# cc13x2_cc26x2 register map
File version: 2.1
CPU: CM4 r0p1, little endian, MPU, FPU, 3 interrupt priority bits
Registers are 32-bit, read-write, reset 0x0 unless marked. A register's access mark holds for its fields unless they carry their own. Offsets are from the block's base; [hi:lo] are bit positions; {n}, {i} and the like mark numbered series.

## EVENT — Event Fabric Component Definition
Base 0x40083000
0x00 CPUIRQSEL0 ro reset 0x4 — Output Selection for CPU Interrupt 0
  [6:0] EV
0x04 CPUIRQSEL1 ro reset 0x9 — Output Selection for CPU Interrupt 1
  [6:0] EV
0x08 CPUIRQSEL2 ro reset 0x1E — Output Selection for CPU Interrupt 2
  [6:0] EV
0x0C CPUIRQSEL3 ro reset 0x1F — Output Selection for CPU Interrupt 3
  [6:0] EV
0x10 CPUIRQSEL4 ro reset 0x7 — Output Selection for CPU Interrupt 4
  [6:0] EV
0x14 CPUIRQSEL5 ro reset 0x24 — Output Selection for CPU Interrupt 5
  [6:0] EV
0x18 CPUIRQSEL6 ro reset 0x1C — Output Selection for CPU Interrupt 6
  [6:0] EV
0x1C CPUIRQSEL7 ro reset 0x22 — Output Selection for CPU Interrupt 7
  [6:0] EV
0x20 CPUIRQSEL8 ro reset 0x23 — Output Selection for CPU Interrupt 8
  [6:0] EV
0x24 CPUIRQSEL9 ro reset 0x1B — Output Selection for CPU Interrupt 9
  [6:0] EV
0x28 CPUIRQSEL10 ro reset 0x1A — Output Selection for CPU Interrupt 10
  [6:0] EV
0x2C CPUIRQSEL11 ro reset 0x19 — Output Selection for CPU Interrupt 11
  [6:0] EV
0x30 CPUIRQSEL12 ro reset 0x8 — Output Selection for CPU Interrupt 12
  [6:0] EV
0x34 CPUIRQSEL13 ro reset 0x1D — Output Selection for CPU Interrupt 13
  [6:0] EV
0x38 CPUIRQSEL14 ro reset 0x18 — Output Selection for CPU Interrupt 14
  [6:0] EV
0x3C CPUIRQSEL15 ro reset 0x10 — Output Selection for CPU Interrupt 15
  [6:0] EV
0x40 CPUIRQSEL16 ro reset 0x11 — Output Selection for CPU Interrupt 16
  [6:0] EV
0x44 CPUIRQSEL17 ro reset 0x12 — Output Selection for CPU Interrupt 17
  [6:0] EV
0x48 CPUIRQSEL18 ro reset 0x13 — Output Selection for CPU Interrupt 18
  [6:0] EV
0x4C CPUIRQSEL19 ro reset 0xC — Output Selection for CPU Interrupt 19
  [6:0] EV
0x50 CPUIRQSEL20 ro reset 0xD — Output Selection for CPU Interrupt 20
  [6:0] EV
0x54 CPUIRQSEL21 ro reset 0xE — Output Selection for CPU Interrupt 21
  [6:0] EV
0x58 CPUIRQSEL22 ro reset 0xF — Output Selection for CPU Interrupt 22
  [6:0] EV
0x5C CPUIRQSEL23 ro reset 0x5D — Output Selection for CPU Interrupt 23
  [6:0] EV
0x60 CPUIRQSEL24 ro reset 0x27 — Output Selection for CPU Interrupt 24
  [6:0] EV
0x64 CPUIRQSEL25 ro reset 0x26 — Output Selection for CPU Interrupt 25
  [6:0] EV
0x68 CPUIRQSEL26 ro reset 0x15 — Output Selection for CPU Interrupt 26
  [6:0] EV
0x6C CPUIRQSEL27 ro reset 0x64 — Output Selection for CPU Interrupt 27
  [6:0] EV
0x70 CPUIRQSEL28 ro reset 0xB — Output Selection for CPU Interrupt 28
  [6:0] EV
0x74 CPUIRQSEL29 ro reset 0x1 — Output Selection for CPU Interrupt 29
  [6:0] EV
0x78 CPUIRQSEL30 — Output Selection for CPU Interrupt 30
  [6:0] EV
0x7C CPUIRQSEL31 ro reset 0x6A — Output Selection for CPU Interrupt 31
  [6:0] EV
0x80 CPUIRQSEL32 ro reset 0x73 — Output Selection for CPU Interrupt 32
  [6:0] EV
0x84 CPUIRQSEL33 ro reset 0x68 — Output Selection for CPU Interrupt 33
  [6:0] EV
0x88 CPUIRQSEL34 ro reset 0x6 — Output Selection for CPU Interrupt 34
  [6:0] EV
0x8C CPUIRQSEL35 ro reset 0x38 — Output Selection for CPU Interrupt 35
  [6:0] EV
0x90 CPUIRQSEL36 ro reset 0x25 — Output Selection for CPU Interrupt 36
  [6:0] EV
0x94 CPUIRQSEL37 ro reset 0x5 — Output Selection for CPU Interrupt 37
  [6:0] EV
0x100 RFCSEL0 ro reset 0x3D — Output Selection for RFC Event 0
  [6:0] EV
0x104 RFCSEL1 ro reset 0x3E — Output Selection for RFC Event 1
  [6:0] EV
0x108 RFCSEL2 ro reset 0x3F — Output Selection for RFC Event 2
  [6:0] EV
0x10C RFCSEL3 ro reset 0x40 — Output Selection for RFC Event 3
  [6:0] EV
0x110 RFCSEL4 ro reset 0x41 — Output Selection for RFC Event 4
  [6:0] EV
0x114 RFCSEL5 ro reset 0x42 — Output Selection for RFC Event 5
  [6:0] EV
0x118 RFCSEL6 ro reset 0x43 — Output Selection for RFC Event 6
  [6:0] EV
0x11C RFCSEL7 ro reset 0x44 — Output Selection for RFC Event 7
  [6:0] EV
0x120 RFCSEL8 ro reset 0x77 — Output Selection for RFC Event 8
  [6:0] EV
0x124 RFCSEL9 reset 0x2 — Output Selection for RFC Event 9
  [6:0] EV
0x200 GPT0ACAPTSEL reset 0x55 — Output Selection for GPT0 0
  [6:0] EV
0x204 GPT0BCAPTSEL reset 0x56 — Output Selection for GPT0 1
  [6:0] EV
0x300 GPT1ACAPTSEL reset 0x57 — Output Selection for GPT1 0
  [6:0] EV
0x304 GPT1BCAPTSEL reset 0x58 — Output Selection for GPT1 1
  [6:0] EV
0x400 GPT2ACAPTSEL reset 0x59 — Output Selection for GPT2 0
  [6:0] EV
0x404 GPT2BCAPTSEL reset 0x5A — Output Selection for GPT2 1
  [6:0] EV
0x508 UDMACH1SSEL ro reset 0x31 — Output Selection for DMA Channel 1 SREQ
  [6:0] EV
0x50C UDMACH1BSEL ro reset 0x30 — Output Selection for DMA Channel 1 REQ
  [6:0] EV
0x510 UDMACH2SSEL ro reset 0x33 — Output Selection for DMA Channel 2 SREQ
  [6:0] EV
0x514 UDMACH2BSEL ro reset 0x32 — Output Selection for DMA Channel 2 REQ
  [6:0] EV
0x518 UDMACH3SSEL ro reset 0x29 — Output Selection for DMA Channel 3 SREQ
  [6:0] EV
0x51C UDMACH3BSEL ro reset 0x28 — Output Selection for DMA Channel 3 REQ
  [6:0] EV
0x520 UDMACH4SSEL ro reset 0x2B — Output Selection for DMA Channel 4 SREQ
  [6:0] EV
0x524 UDMACH4BSEL ro reset 0x2A — Output Selection for DMA Channel 4 REQ
  [6:0] EV
0x528 UDMACH5SSEL ro reset 0x35 — Output Selection for DMA Channel 5 SREQ
  [6:0] EV
0x52C UDMACH5BSEL ro reset 0x34 — Output Selection for DMA Channel 5 REQ
  [6:0] EV
0x530 UDMACH6SSEL ro reset 0x37 — Output Selection for DMA Channel 6 SREQ
  [6:0] EV
0x534 UDMACH6BSEL ro reset 0x36 — Output Selection for DMA Channel 6 REQ
  [6:0] EV
0x538 UDMACH7SSEL ro reset 0x75 — Output Selection for DMA Channel 7 SREQ
  [6:0] EV
0x53C UDMACH7BSEL ro reset 0x76 — Output Selection for DMA Channel 7 REQ
  [6:0] EV
0x540 UDMACH8SSEL ro reset 0x74 — Output Selection for DMA Channel 8 SREQ ingle request is ignored for this channel
  [6:0] EV
0x544 UDMACH8BSEL ro reset 0x74 — Output Selection for DMA Channel 8 REQ
  [6:0] EV
0x548 UDMACH9SSEL reset 0x45 — Output Selection for DMA Channel 9 SREQ MA_DONE for the corresponding DMA channel is available as interrupt on GPT0 as GPT0:RIS.DMAARIS
  [6:0] EV
0x54C UDMACH9BSEL reset 0x4D — Output Selection for DMA Channel 9 REQ MA_DONE for the corresponding DMA channel is available as interrupt on GPT0 as GPT0:RIS.DMAARIS
  [6:0] EV
0x550 UDMACH10SSEL reset 0x46 — Output Selection for DMA Channel 10 SREQ MA_DONE for the corresponding DMA channel is available as interrupt on GPT0 as GPT0:RIS.DMABRIS
  [6:0] EV
0x554 UDMACH10BSEL reset 0x4E — Output Selection for DMA Channel 10 REQ MA_DONE for the corresponding DMA channel is available as interrupt on GPT0 as GPT0:RIS.DMABRIS
  [6:0] EV
0x558 UDMACH11SSEL reset 0x47 — Output Selection for DMA Channel 11 SREQ MA_DONE for the corresponding DMA channel is available as interrupt on GPT1 as GPT1:RIS.DMAARIS
  [6:0] EV
0x55C UDMACH11BSEL reset 0x4F — Output Selection for DMA Channel 11 REQ MA_DONE for the corresponding DMA channel is available as interrupt on GPT1 as GPT1:RIS.DMAARIS
  [6:0] EV
0x560 UDMACH12SSEL reset 0x48 — Output Selection for DMA Channel 12 SREQ MA_DONE for the corresponding DMA channel is available as interrupt on GPT1 as GPT1:RIS.DMABRIS
  [6:0] EV
0x564 UDMACH12BSEL reset 0x50 — Output Selection for DMA Channel 12 REQ MA_DONE for the corresponding DMA channel is available as interrupt on GPT1 as GPT1:RIS.DMABRIS
  [6:0] EV
0x56C UDMACH13BSEL ro reset 0x3 — Output Selection for DMA Channel 13 REQ
  [6:0] EV
0x574 UDMACH14BSEL reset 0x1 — Output Selection for DMA Channel 14 REQ
  [6:0] EV
0x57C UDMACH15BSEL ro reset 0x7 — Output Selection for DMA Channel 15 REQ
  [6:0] EV
0x580 UDMACH16SSEL ro reset 0x2D — Output Selection for DMA Channel 16 SREQ
  [6:0] EV
0x584 UDMACH16BSEL ro reset 0x2C — Output Selection for DMA Channel 16 REQ
  [6:0] EV
0x588 UDMACH17SSEL ro reset 0x2F — Output Selection for DMA Channel 17 SREQ
  [6:0] EV
0x58C UDMACH17BSEL ro reset 0x2E — Output Selection for DMA Channel 17 REQ
  [6:0] EV
0x5A8 UDMACH21SSEL ro reset 0x64 — Output Selection for DMA Channel 21 SREQ
  [6:0] EV
0x5AC UDMACH21BSEL ro reset 0x64 — Output Selection for DMA Channel 21 REQ
  [6:0] EV
0x5B0 UDMACH22SSEL ro reset 0x65 — Output Selection for DMA Channel 22 SREQ
  [6:0] EV
0x5B4 UDMACH22BSEL ro reset 0x65 — Output Selection for DMA Channel 22 REQ
  [6:0] EV
0x5B8 UDMACH23SSEL ro reset 0x66 — Output Selection for DMA Channel 23 SREQ
  [6:0] EV
0x5BC UDMACH23BSEL ro reset 0x66 — Output Selection for DMA Channel 23 REQ
  [6:0] EV
0x5C0 UDMACH24SSEL ro reset 0x67 — Output Selection for DMA Channel 24 SREQ
  [6:0] EV
0x5C4 UDMACH24BSEL ro reset 0x67 — Output Selection for DMA Channel 24 REQ
  [6:0] EV
0x600 GPT3ACAPTSEL reset 0x5B — Output Selection for GPT3 0
  [6:0] EV
0x604 GPT3BCAPTSEL reset 0x5C — Output Selection for GPT3 1
  [6:0] EV
0x700 AUXSEL0 reset 0x10 — Output Selection for AUX Subscriber 0
  [6:0] EV
0x800 CM3NMISEL0 ro reset 0x63 — Output Selection for NMI Subscriber 0
  [6:0] EV
0x900 I2SSTMPSEL0 reset 0x5F — Output Selection for I2S Subscriber 0
  [6:0] EV
0xA00 FRZSEL0 reset 0x78 — Output Selection for FRZ Subscriber he halted debug signal is passed to peripherals such as the General Purpose Timer, Sensor Controller with Digital and Analog Peripherals (AUX), Radio, and RTC. When the system CPU halts, the connected peripherals that have freeze enabled also halt. The programmable output can be set to static values of 0 or 1, and can also be set to pass the halted signal.
  [6:0] EV
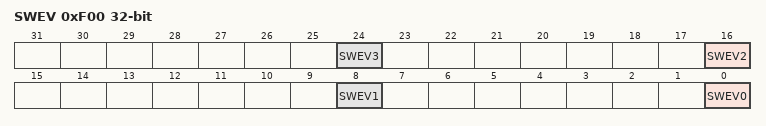
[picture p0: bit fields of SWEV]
0xF00 SWEV — Set or Clear Software Events
  [8n] SWEV{n} (n=0..3)
